AUTOSAR XML (schema 4-2-1)
package /ComponentTypes
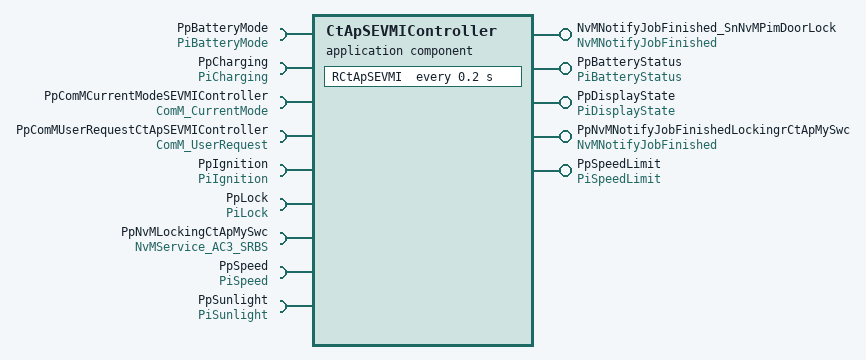
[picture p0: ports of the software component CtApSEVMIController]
  application sw component type CtApSEVMIController
    5 x provide port:
      NvMNotifyJobFinished_SnNvMPimDoorLock: server-com-spec{operation=JobFinished, queue-length=1}, provided-interface=NvMNotifyJobFinished
      PpBatteryStatus: nonqueued-sender-com-spec{data-element=DeBatteryStatus, init-value=constant-reference=CBatteryStatus}, provided-interface=PiBatteryStatus
      PpDisplayState: nonqueued-sender-com-spec=data-element=DeLockingWriteRequestPending, provided-interface=PiDisplayState
      PpNvMNotifyJobFinishedLockingrCtApMySwc: server-com-spec{operation=JobFinished, queue-length=1}, provided-interface=NvMNotifyJobFinished
      PpSpeedLimit: nonqueued-sender-com-spec{data-element=DeSpeedLimit, init-value=constant-reference=CSpeedLimit}, provided-interface=PiSpeedLimit
    9 x require port:
      PpBatteryMode: mode-switch-receiver-com-spec{enhanced-mode-api=false, supports-asynchronous-mode-switch=false}, required-interface=PiBatteryMode
      PpCharging: nonqueued-receiver-com-spec{data-element=DeCharging, filter=data-filter-type=ALWAYS, init-value=constant-reference=CCharging}, required-interface=PiCharging
      PpComMCurrentModeSEVMIController: mode-switch-receiver-com-spec{enhanced-mode-api=false, supports-asynchronous-mode-switch=false}, required-interface=ComM_CurrentMode
      PpComMUserRequestCtApSEVMIController: required-interface=ComM_UserRequest
      PpIgnition: nonqueued-receiver-com-spec{data-element=DeIgnition, filter=data-filter-type=ALWAYS, init-value=constant-reference=CIgnition}, required-interface=PiIgnition
      PpLock: nonqueued-receiver-com-spec{data-element=DeLock, filter=data-filter-type=ALWAYS, init-value=constant-reference=CCarLocked}, required-interface=PiLock
      PpNvMLockingCtApMySwc: required-interface=NvMService_AC3_SRBS
      PpSpeed: required-interface=PiSpeed
      PpSunlight: nonqueued-receiver-com-spec{data-element=DeSunlight, filter=data-filter-type=ALWAYS, init-value=constant-reference=CSunlight}, required-interface=PiSunlight
    behavior CtApSEVMIController_InternalBehavior: data-type-mapping=ApMappingSet
      exclusive area ExBatteryStatus
      ar-typed-per-instance-memorys:
        data SnNvMPimDoorLock_MirrorBlock: sw-calibration-access=READ-ONLY, type=AdtLock
      operation invoked event OIT_PpNvMNotifyJobFinishedLockingrCtApMySwc_JobFinished_NvMNotifyJobFinished_SnNvMPimDoorLock_JobFinished: start-on-event=PpNvMNotifyJobFinishedLockingrCtApMySwc_JobFinished, operation=NvMNotifyJobFinished_SnNvMPimDoorLock.JobFinished
      init event RCtApMySwc_InitEvent: start-on-event=RCtApMySwc_Init
      timing event TMT_RCtApSEVMI: start-on-event=RCtApSEVMI, period=0.2
      swc mode switch event MST_RCtBatteryMode_0: start-on-event=RCtBatteryMode, activation=ON-ENTRY, mode=PpBatteryMode.BatteryModes.NORMAL
      explicit-inter-runnable-variables:
        data IrvLockStateOld: type=AdtLock, init-value=constant-reference=CCarLocked
      4 x runnable:
        PpNvMNotifyJobFinishedLockingrCtApMySwc_JobFinished
          data-send-points:
            access SEND_PpDisplayState_DeLockingWriteRequestPending: accessed-variable=PpDisplayState.DeLockingWriteRequestPending
        RCtApMySwc_Init: can-enter-exclusive-area=ExBatteryStatus
          data-receive-point-by-arguments:
            access REC_PpLock_DeLock: accessed-variable=PpLock.DeLock
        RCtApSEVMI: can-enter-exclusive-area=ExBatteryStatus, mode-access-points=[PpComMCurrentModeSEVMIController.currentMode, PpBatteryMode.BatteryModes]
          data-receive-point-by-arguments:
            4 x access:
              REC_PpCharging_DeCharging: accessed-variable=PpCharging.DeCharging
              REC_PpIgnition_DeIgnition: accessed-variable=PpIgnition.DeIgnition
              REC_PpLock_DeLock: accessed-variable=PpLock.DeLock
              REC_PpSunlight_DeSunlight: accessed-variable=PpSunlight.DeSunlight
          data-send-points:
            access SEND_PpBatteryStatus_DeBatteryStatus: accessed-variable=PpBatteryStatus.DeBatteryStatus
            access SEND_PpSpeedLimit_DeSpeedLimit: accessed-variable=PpSpeedLimit.DeSpeedLimit
          read-local-variables:
            access READ_IrvLockStateOld: accessed-variable=IrvLockStateOld
          4 x sync call, all with timeout=0:
            SC_PpComMUserRequestCtApSEVMIController_RequestComMode: operation=PpComMUserRequestCtApSEVMIController.RequestComMode
            SC_PpNvMLockingCtApMySwc_GetErrorStatus: operation=PpNvMLockingCtApMySwc.GetErrorStatus
            SC_PpNvMLockingCtApMySwc_WriteBlock: operation=PpNvMLockingCtApMySwc.WriteBlock
            SC_PpSpeed_ReadChannel: operation=PpSpeed.ReadChannel
          written-local-variables:
            access WRITE_IrvLockStateOld: accessed-variable=IrvLockStateOld
        RCtBatteryMode
          data-send-points:
            access SEND_PpBatteryStatus_DeBatteryStatus: accessed-variable=PpBatteryStatus.DeBatteryStatus
            access SEND_PpSpeedLimit_DeSpeedLimit: accessed-variable=PpSpeedLimit.DeSpeedLimit
      swc service dependency SnNvMPimDoorLock: assigned-datas=role-based-data-assignment={role=ramBlock, used-data-element=SnNvMPimDoorLock_MirrorBlock}
        assigned-ports:
          port-prototype=NvMNotifyJobFinished_SnNvMPimDoorLock, role=NvMNotifyJobFinished
          port-prototype=PpNvMLockingCtApMySwc, role=NvMService_AC3_SRBS
          port-prototype=NvMNotifyJobFinished_SnNvMPimDoorLock, role=NvMNotifyJobFinished
          port-prototype=PpNvMLockingCtApMySwc, role=NvMService_AC3_SRBS
        service-needs:
          nv block needs SnNvMPimDoorLock: n-data-sets=0, ram-block-status-control=API, readonly=false, reliability=NO-PROTECTION, resistant-to-changed-sw=false, restore-at-start=true, store-at-shutdown=true, write-only-once=false
  swc implementation CtApSEVMIController_Implementation: behavior=CtApSEVMIController_InternalBehavior
    code-descriptors:
      code Default: artifact-descriptors=autosar-engineering-object={short-label=Default, category=SWSRC}
